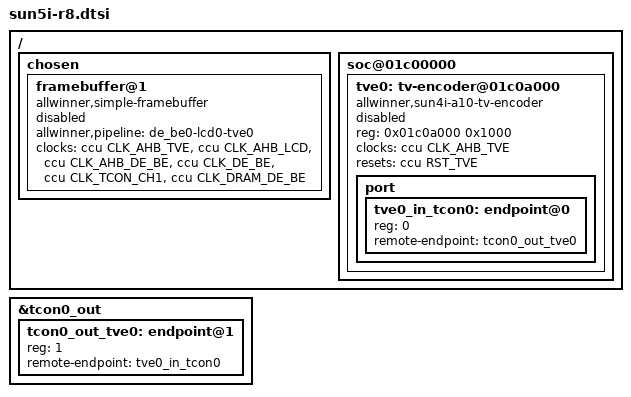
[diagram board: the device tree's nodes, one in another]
/*
 * Copyright 2015 Free Electrons
 * Copyright 2015 NextThing Co
 *
 * Maxime Ripard <maxime.ripard@free-electrons.com>
 *
 * This file is dual-licensed: you can use it either under the terms
 * of the GPL or the X11 license, at your option. Note that this dual
 * licensing only applies to this file, and not this project as a
 * whole.
 *
 *  a) This file is free software; you can redistribute it and/or
 *     modify it under the terms of the GNU General Public License as
 *     published by the Free Software Foundation; either version 2 of the
 *     License, or (at your option) any later version.
 *
 *     This file is distributed in the hope that it will be useful,
 *     but WITHOUT ANY WARRANTY; without even the implied warranty of
 *     MERCHANTABILITY or FITNESS FOR A PARTICULAR PURPOSE.  See the
 *     GNU General Public License for more details.
 *
 * Or, alternatively,
 *
 *  b) Permission is hereby granted, free of charge, to any person
 *     obtaining a copy of this software and associated documentation
 *     files (the "Software"), to deal in the Software without
 *     restriction, including without limitation the rights to use,
 *     copy, modify, merge, publish, distribute, sublicense, and/or
 *     sell copies of the Software, and to permit persons to whom the
 *     Software is furnished to do so, subject to the following
 *     conditions:
 *
 *     The above copyright notice and this permission notice shall be
 *     included in all copies or substantial portions of the Software.
 *
 *     THE SOFTWARE IS PROVIDED "AS IS", WITHOUT WARRANTY OF ANY KIND,
 *     EXPRESS OR IMPLIED, INCLUDING BUT NOT LIMITED TO THE WARRANTIES
 *     OF MERCHANTABILITY, FITNESS FOR A PARTICULAR PURPOSE AND
 *     NONINFRINGEMENT. IN NO EVENT SHALL THE AUTHORS OR COPYRIGHT
 *     HOLDERS BE LIABLE FOR ANY CLAIM, DAMAGES OR OTHER LIABILITY,
 *     WHETHER IN AN ACTION OF CONTRACT, TORT OR OTHERWISE, ARISING
 *     FROM, OUT OF OR IN CONNECTION WITH THE SOFTWARE OR THE USE OR
 *     OTHER DEALINGS IN THE SOFTWARE.
 */

#include "sun5i-a13.dtsi"

/ {
	chosen {
		framebuffer@1 {
			compatible = "allwinner,simple-framebuffer",
				     "simple-framebuffer";
			allwinner,pipeline = "de_be0-lcd0-tve0";
			clocks = <&ccu CLK_AHB_TVE>, <&ccu CLK_AHB_LCD>,
				 <&ccu CLK_AHB_DE_BE>, <&ccu CLK_DE_BE>,
				 <&ccu CLK_TCON_CH1>, <&ccu CLK_DRAM_DE_BE>;
			status = "disabled";
		};
	};

	soc@01c00000 {
		tve0: tv-encoder@01c0a000 {
			compatible = "allwinner,sun4i-a10-tv-encoder";
			reg = <0x01c0a000 0x1000>;
			clocks = <&ccu CLK_AHB_TVE>;
			resets = <&ccu RST_TVE>;
			status = "disabled";

			port {
				#address-cells = <1>;
				#size-cells = <0>;

				tve0_in_tcon0: endpoint@0 {
					reg = <0>;
					remote-endpoint = <&tcon0_out_tve0>;
				};
			};
		};
	};
};

&tcon0_out {
	tcon0_out_tve0: endpoint@1 {
		reg = <1>;
		remote-endpoint = <&tve0_in_tcon0>;
	};
};
